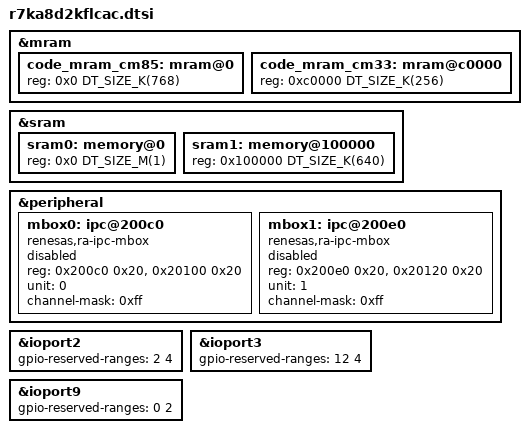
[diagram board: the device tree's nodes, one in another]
/*
 * Copyright (c) 2025-2026 Renesas Electronics Corporation
 *
 * SPDX-License-Identifier: Apache-2.0
 */

#include <arm/renesas/ra/ra8/r7ka8d2xf.dtsi>

&mram {
	#address-cells = <1>;
	#size-cells = <1>;

	code_mram_cm85: mram@0 {
		reg = <0x0 DT_SIZE_K(768)>;
		#address-cells = <1>;
		#size-cells = <1>;
		ranges;
	};

	code_mram_cm33: mram@c0000 {
		reg = <0xc0000 DT_SIZE_K(256)>;
		#address-cells = <1>;
		#size-cells = <1>;
		ranges;
	};
};

&sram {
	#address-cells = <1>;
	#size-cells = <1>;

	sram0: memory@0 {
		reg = <0x0 DT_SIZE_M(1)>;
		#address-cells = <1>;
		#size-cells = <1>;
		ranges;
	};

	sram1: memory@100000 {
		reg = <0x100000 DT_SIZE_K(640)>;
		#address-cells = <1>;
		#size-cells = <1>;
		ranges;
	};
};

&peripheral {
	mbox0: ipc@200c0 {
		compatible = "renesas,ra-ipc-mbox";
		reg = <0x200c0 0x20>, <0x20100 0x20>;
		reg-names = "ipc00", "ipc10";
		unit = <0>;
		channel-mask = <0xff>;
		#mbox-cells = <1>;
		status = "disabled";
	};

	mbox1: ipc@200e0 {
		compatible = "renesas,ra-ipc-mbox";
		reg = <0x200e0 0x20>, <0x20120 0x20>;
		reg-names = "ipc01", "ipc11";
		unit = <1>;
		channel-mask = <0xff>;
		#mbox-cells = <1>;
		status = "disabled";
	};
};

&ioport2 {
	gpio-reserved-ranges = <2 4>;
};

&ioport3 {
	gpio-reserved-ranges = <12 4>;
};

&ioport9 {
	gpio-reserved-ranges = <0 2>;
};
